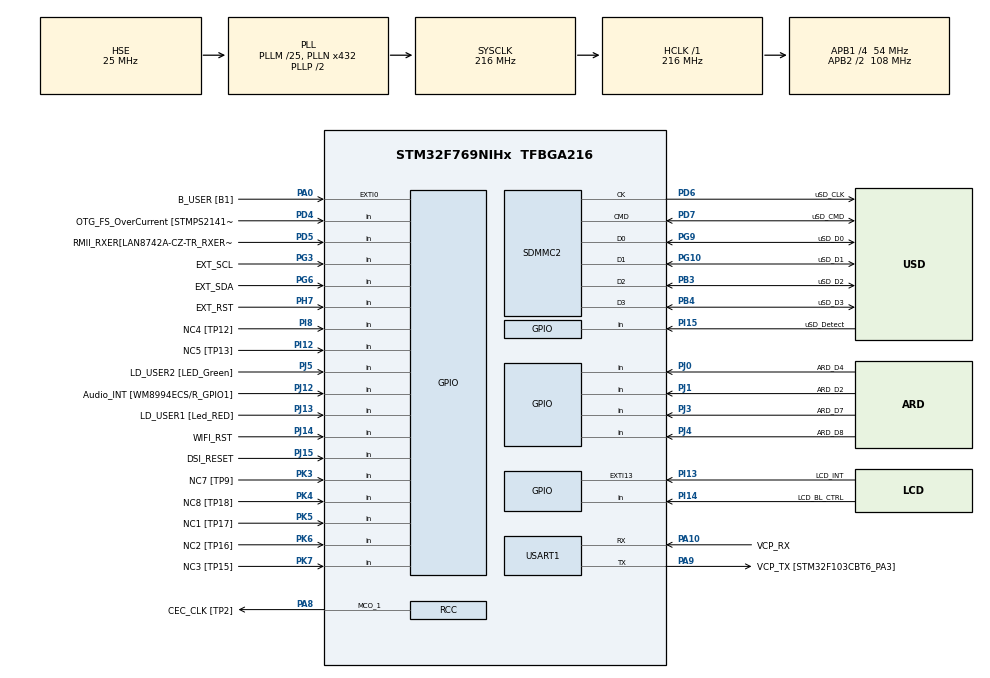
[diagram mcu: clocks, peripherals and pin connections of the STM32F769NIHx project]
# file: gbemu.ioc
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DSIHOST_CKN.GPIO_Label=DSI_CK_N
DSIHOST_CKN.Signal=DSIHOST_CKN
DSIHOST_CKP.GPIO_Label=DSI_CK_P
DSIHOST_CKP.Signal=DSIHOST_CKP
DSIHOST_D0N.GPIO_Label=DSI_D0_N
DSIHOST_D0N.Signal=DSIHOST_D0N
DSIHOST_D0P.GPIO_Label=DSI_D0_p
DSIHOST_D0P.Signal=DSIHOST_D0P
DSIHOST_D1N.GPIO_Label=DSI_D1_N
DSIHOST_D1N.Signal=DSIHOST_D1N
DSIHOST_D1P.GPIO_Label=DSI_D1_P
DSIHOST_D1P.Signal=DSIHOST_D1P
Dma.Request0=SDMMC2_RX
Dma.Request1=SDMMC2_TX
Dma.SDMMC2_RX.0.Direction=DMA_PERIPH_TO_MEMORY
Dma.SDMMC2_RX.0.FIFOMode=DMA_FIFOMODE_ENABLE
Dma.SDMMC2_RX.0.FIFOThreshold=DMA_FIFO_THRESHOLD_FULL
Dma.SDMMC2_RX.0.Instance=DMA2_Stream0
Dma.SDMMC2_RX.0.MemBurst=DMA_MBURST_INC4
Dma.SDMMC2_RX.0.MemDataAlignment=DMA_MDATAALIGN_WORD
Dma.SDMMC2_RX.0.MemInc=DMA_MINC_ENABLE
Dma.SDMMC2_RX.0.Mode=DMA_PFCTRL
Dma.SDMMC2_RX.0.PeriphBurst=DMA_PBURST_INC4
Dma.SDMMC2_RX.0.PeriphDataAlignment=DMA_PDATAALIGN_WORD
Dma.SDMMC2_RX.0.PeriphInc=DMA_PINC_DISABLE
Dma.SDMMC2_RX.0.Priority=DMA_PRIORITY_LOW
Dma.SDMMC2_TX.1.Direction=DMA_MEMORY_TO_PERIPH
Dma.SDMMC2_TX.1.FIFOMode=DMA_FIFOMODE_ENABLE
Dma.SDMMC2_TX.1.FIFOThreshold=DMA_FIFO_THRESHOLD_FULL
Dma.SDMMC2_TX.1.Instance=DMA2_Stream5
Dma.SDMMC2_TX.1.MemBurst=DMA_MBURST_INC4
Dma.SDMMC2_TX.1.MemDataAlignment=DMA_MDATAALIGN_WORD
Dma.SDMMC2_TX.1.MemInc=DMA_MINC_ENABLE
Dma.SDMMC2_TX.1.Mode=DMA_PFCTRL
Dma.SDMMC2_TX.1.PeriphBurst=DMA_PBURST_INC4
Dma.SDMMC2_TX.1.PeriphDataAlignment=DMA_PDATAALIGN_WORD
Dma.SDMMC2_TX.1.PeriphInc=DMA_PINC_DISABLE
Dma.SDMMC2_TX.1.Priority=DMA_PRIORITY_LOW
FATFS.BSP.number=1
FATFS.USE_DMA_CODE_SD=1
FATFS._MAX_SS=512
FATFS._MIN_SS=512
FATFS0.BSP.STBoard=false
FATFS0.BSP.api=Unknown
FATFS0.BSP.i2caddr=0
FATFS0.BSP.instance=PI15
FATFS0.BSP.ip=GPIO
FATFS0.BSP.mode=Input
FATFS0.BSP.name=Detect_SDIO
FATFS0.BSP.solution=PI15
FREERTOS.Tasks01=defaultTask,-3,128,StartDefaultTask,Default,NULL,Dynamic,NULL,NULL;cpu_task,-1,512,cpu_start,Default,NULL,Dynamic,NULL,NULL;ui_task,0,512,ui_start,Default,NULL,Dynamic,NULL,NULL
FREERTOS.configUSE_NEWLIB_REENTRANT=1
Mcu.Family=STM32F7
Mcu.Name=STM32F769NIHx
Mcu.Package=TFBGA216
NVIC.DMA2_Stream0_IRQn=true\:5\:0\:false\:false\:true\:true\:false\:true
NVIC.DMA2_Stream5_IRQn=true\:5\:0\:false\:false\:true\:true\:false\:true
NVIC.PriorityGroup=NVIC_PRIORITYGROUP_4
NVIC.SDMMC2_IRQn=true\:5\:0\:false\:false\:true\:true\:true\:true
NVIC.TIM1_UP_TIM10_IRQn=true\:15\:0\:false\:false\:true\:false\:false\:true
NVIC.TimeBase=TIM1_UP_TIM10_IRQn
NVIC.TimeBaseIP=TIM1
PA0/WKUP.GPIO_Label=B_USER [B1]
PA0/WKUP.Signal=GPXTI0
PA1.GPIO_Label=RMII_REF_CLK [LAN8742A-CZ-TR_REFCLK0]
PA1.Signal=ETH_REF_CLK
PA10.GPIO_Label=VCP_RX 
PA10.Mode=Asynchronous
PA10.Signal=USART1_RX
PA11.GPIO_Label=SPI2_NSS
PA11.Signal=SPI2_NSS
PA12.GPIO_Label=ARD_D13/SCK
PA12.GPIO_Mode=GPIO_MODE_AF_PP
PA12.GPIO_PuPd=GPIO_NOPULL
PA12.GPIO_Speed=GPIO_SPEED_FREQ_LOW
PA12.Signal=SPI2_SCK
PA13.GPIO_Label=SWDIO
PA13.Mode=Serial_Wire
PA13.Signal=SYS_JTMS-SWDIO
PA14.GPIO_Label=SWCLK
PA14.Mode=Serial_Wire
PA14.Signal=SYS_JTCK-SWCLK
PA15.GPIO_Label=CEC
PA15.Signal=CEC
PA2.GPIO_Label=RMII_MDIO [LAN8742A-CZ-TR_MDIO]
PA2.Signal=ETH_MDIO
PA3.GPIO_Label=ULPI_D0 [USB3320C-EZK_D0]
PA3.Signal=USB_OTG_HS_ULPI_D0
PA4.GPIO_Label=ARD_A1
PA4.Signal=ADCx_IN4
PA5.GPIO_Label=ULPI_CLK [USB3320C-EZK_CLKOUT]
PA5.Signal=USB_OTG_HS_ULPI_CK
PA6.GPIO_Label=ARD_A0
PA6.Signal=ADCx_IN6
PA7.GPIO_Label=RMII_CRS_DV [LAN8742A-CZ-TR_CRS_DV]
PA7.Signal=ETH_CRS_DV
PA8.GPIO_Label=CEC_CLK [TP2]
PA8.Mode=Clock-out-1
PA8.Signal=RCC_MCO_1
PA9.GPIO_Label=VCP_TX [STM32F103CBT6_PA3]
PA9.GPIO_Mode=GPIO_MODE_AF_PP
PA9.GPIO_PuPd=GPIO_NOPULL
PA9.GPIO_Speed=GPIO_SPEED_FREQ_LOW
PA9.Mode=Asynchronous
PA9.Signal=USART1_TX
PB0.GPIO_Label=ULPI_D1 [USB3320C-EZK_D1]
PB0.Signal=USB_OTG_HS_ULPI_D1
PB1.GPIO_Label=ULPI_D2 [USB3320C-EZK_D2]
PB1.Signal=USB_OTG_HS_ULPI_D2
PB10.GPIO_Label=ULPI_D3 [USB3320C-EZK_D3]
PB10.Signal=USB_OTG_HS_ULPI_D3
PB11.GPIO_Label=ULPI_D4 [USB3320C-EZK_D4]
PB11.Signal=USB_OTG_HS_ULPI_D4
PB12.GPIO_Label=ULPI_D5 [USB3320C-EZK_D5]
PB12.Signal=USB_OTG_HS_ULPI_D5
PB13.GPIO_Label=ULPI_D6 [USB3320C-EZK_D6]
PB13.Signal=USB_OTG_HS_ULPI_D6
PB14.GPIO_Label=ARDUINO MISO/D12
PB14.GPIO_Mode=GPIO_MODE_AF_PP
PB14.GPIO_PuPd=GPIO_NOPULL
PB14.GPIO_Speed=GPIO_SPEED_FREQ_LOW
PB14.Signal=SPI2_MISO
PB15.GPIO_Label=ARDUINO MOSI/PWM/D11
PB15.GPIO_Mode=GPIO_MODE_AF_PP
PB15.GPIO_PuPd=GPIO_NOPULL
PB15.GPIO_Speed=GPIO_SPEED_FREQ_LOW
PB15.Signal=SPI2_MOSI
PB2.Signal=QUADSPI_CLK
PB3.GPIO_Label=uSD_D2
PB3.Mode=SD_4_bits_Wide_bus
PB3.Signal=SDMMC2_D2
PB4.GPIO_Label=uSD_D3
PB4.Mode=SD_4_bits_Wide_bus
PB4.Signal=SDMMC2_D3
PB5.GPIO_Label=ULPI_D7 [USB3320C-EZK_D7]
PB5.Signal=USB_OTG_HS_ULPI_D7
PB6.GPIO_Label=QSPI_NCS [N25Q128A13EF840E_S]
PB6.Signal=QUADSPI_BK1_NCS
PB7.GPIO_Label=AUDIO_SDA [WM8994ECS/R_SDA]
PB7.Signal=I2C4_SDA
PB8.GPIO_Label=ARDUINO SCL/D15
PB8.GPIO_Mode=GPIO_MODE_AF_OD
PB8.GPIO_PuPd=GPIO_NOPULL
PB8.GPIO_Speed=GPIO_SPEED_FREQ_LOW
PB8.Signal=I2C1_SCL
PB9.GPIO_Label=ARDUINO SDA/D14
PB9.GPIO_Mode=GPIO_MODE_AF_OD
PB9.GPIO_PuPd=GPIO_NOPULL
PB9.GPIO_Speed=GPIO_SPEED_FREQ_LOW
PB9.Signal=I2C1_SDA
PC0.GPIO_Label=ULPI_STP [USB3320C-EZK_STP]
PC0.Signal=USB_OTG_HS_ULPI_STP
PC1.GPIO_Label=RMII_MDC [LAN8742A-CZ-TR_MDC]
PC1.Signal=ETH_MDC
PC10.GPIO_Label=QSPI_D1 [MT25QL512ABB1EW9_DQ1]
PC10.Signal=QUADSPI_BK1_IO1
PC11.GPIO_Label=DFSDM_DATIN5 [TP100]
PC11.Signal=S_DATAIN5DFSDM1
PC12.GPIO_Label=WIFI_RX
PC12.Signal=UART5_TX
PC14/OSC32_IN.GPIO_Label=RCC_OSC32_IN
PC14/OSC32_IN.Signal=RCC_OSC32_IN
PC15/OSC32_OUT.GPIO_Label=RCC_OSC32_OUT
PC15/OSC32_OUT.Signal=RCC_OSC32_OUT
PC2.GPIO_Label=ARD_A2
PC2.Signal=ADCx_IN12
PC3.GPIO_Label=DFSDM_DATIN1 [TP101]
PC3.Signal=S_DATAIN1DFSDM1
PC4.GPIO_Label=RMII_RXD0 [LAN8742A-CZ-TR_RXD0]
PC4.Signal=ETH_RXD0
PC5.GPIO_Label=RMII_RXD1 [LAN8742A-CZ-TR_RXD1]
PC5.Signal=ETH_RXD1
PC6.GPIO_Label=ARDUINO TX/D1
PC6.Signal=USART6_TX
PC7.GPIO_Label=ARD_D0/RX
PC7.Signal=USART6_RX
PC8.GPIO_Label=ARD_D5/PWM
PC8.Signal=S_TIM3_CH3
PC9.GPIO_Label=QSPI_D0 [N25Q128A13EF840E_DQ0]
PC9.Signal=QUADSPI_BK1_IO0
PD0.GPIO_Label=FMC_D2 [MT48LC4M32B2B5-6A_DQ2]
PD0.Signal=FMC_D2_DA2
PD1.GPIO_Label=FMC_D3 [MT48LC4M32B2B5-6A_DQ3]
PD1.Signal=FMC_D3_DA3
PD10.GPIO_Label=FMC_D15 [MT48LC4M32B2B5-6A_DQ15]
PD10.Signal=FMC_D15_DA15
PD11.GPIO_Label=SPDIF_TX [TP20]
PD11.Signal=SAI2_SD_A
PD12.GPIO_Label=AUDIO_SCL [WM8994ECS/R_SCLK]
PD12.Signal=I2C4_SCL
PD13.GPIO_Label=QSPI_D3 [N25Q128A13EF840E_DQ3]
PD13.Signal=QUADSPI_BK1_IO3
PD14.GPIO_Label=FMC_D0 [MT48LC4M32B2B5-6A_DQ0]
PD14.Signal=FMC_D0_DA0
PD15.GPIO_Label=FMC_D1 [MT48LC4M32B2B5-6A_DQ1]
PD15.Signal=FMC_D1_DA1
PD2.GPIO_Label=WIFI_TX
PD2.Signal=UART5_RX
PD3.GPIO_Label=DFSDM_CKOUT [TP102]
PD3.Signal=S_CKOUTDFSDM1
PD4.GPIO_Label=OTG_FS_OverCurrent [STMPS2141STR_Fault]
PD4.Signal=GPIO_Input
PD5.GPIO_Label=RMII_RXER[LAN8742A-CZ-TR_RXERR]
PD5.Signal=GPIO_Input
PD6.GPIO_Label=uSD_CLK
PD6.Mode=SD_4_bits_Wide_bus
PD6.Signal=SDMMC2_CK
PD7.GPIO_Label=uSD_CMD
PD7.Mode=SD_4_bits_Wide_bus
PD7.Signal=SDMMC2_CMD
PD8.GPIO_Label=FMC_D13 [MT48LC4M32B2B5-6A_DQ13]
PD8.Signal=FMC_D13_DA13
PD9.GPIO_Label=FMC_D14 [MT48LC4M32B2B5-6A_DQ14]
PD9.Signal=FMC_D14_DA14
PE0.GPIO_Label=FMC_NBL0 [MT48LC4M32B2B5-6A_DQM0]
PE0.Signal=FMC_NBL0
PE1.GPIO_Label=FMC_NBL1 [MT48LC4M32B2B5-6A_DQM1]
PE1.Signal=FMC_NBL1
PE10.GPIO_Label=FMC_D7 [MT48LC4M32B2B5-6A_DQ7]
PE10.Signal=FMC_D7_DA7
PE11.GPIO_Label=FMC_D8 [MT48LC4M32B2B5-6A_DQ8]
PE11.Signal=FMC_D8_DA8
PE12.GPIO_Label=FMC_D9 [MT48LC4M32B2B5-6A_DQ9]
PE12.Signal=FMC_D9_DA9
PE13.GPIO_Label=FMC_D10 [MT48LC4M32B2B5-6A_DQ10]
PE13.Signal=FMC_D10_DA10
PE14.GPIO_Label=FMC_D11 [MT48LC4M32B2B5-6A_DQ11]
PE14.Signal=FMC_D11_DA11
PE15.GPIO_Label=FMC_D12 [MT48LC4M32B2B5-6A_DQ12]
PE15.Signal=FMC_D12_DA12
PE2.GPIO_Label=QSPI_D2 [N25Q128A13EF840E_DQ2]
PE2.Signal=QUADSPI_BK1_IO2
PE3.GPIO_Label=SAI1_SDB [WM8994ECS/R_ADCDAT1]
PE3.Signal=SAI1_SD_B
PE4.GPIO_Label=SAI1_FSA [WM8994ECS/R_LRCLK1]
PE4.Signal=SAI1_FS_A
PE5.GPIO_Label=SAI1_SCKA [WM8994ECS/R_BCLK1]
PE5.Signal=SAI1_SCK_A
PE6.GPIO_Label=SAI1_SDA [WM8994ECS/R_DACDAT1]
PE6.Signal=SAI1_SD_A
PE7.GPIO_Label=FMC_D4 [MT48LC4M32B2B5-6A_DQ4]
PE7.Signal=FMC_D4_DA4
PE8.GPIO_Label=FMC_D5 [MT48LC4M32B2B5-6A_DQ5]
PE8.Signal=FMC_D5_DA5
PE9.GPIO_Label=FMC_D6 [MT48LC4M32B2B5-6A_DQ6]
PE9.Signal=FMC_D6_DA6
PF0.GPIO_Label=FMC_A0 [MT48LC4M32B2B5-6A_A0]
PF0.Signal=FMC_A0
PF1.GPIO_Label=FMC_A1 [MT48LC4M32B2B5-6A_A1]
PF1.Signal=FMC_A1
PF10.GPIO_Label=ARDUINO A1
PF10.GPIO_Mode=GPIO_MODE_ANALOG
PF10.GPIO_PuPd=GPIO_NOPULL
PF10.Signal=ADC3_IN8
PF11.GPIO_Label=FMC_SDNRAS [MT48LC4M32B2B5-6A_RAS]
PF11.Signal=FMC_SDNRAS
PF12.GPIO_Label=FMC_A6 [MT48LC4M32B2B5-6A_A6]
PF12.Signal=FMC_A6
PF13.GPIO_Label=FMC_A7 [MT48LC4M32B2B5-6A_A7]
PF13.Signal=FMC_A7
PF14.GPIO_Label=FMC_A8 [MT48LC4M32B2B5-6A_A8]
PF14.Signal=FMC_A8
PF15.GPIO_Label=FMC_A9 [MT48LC4M32B2B5-6A_A9]
PF15.Signal=FMC_A9
PF2.GPIO_Label=FMC_A2 [MT48LC4M32B2B5-6A_A2]
PF2.Signal=FMC_A2
PF3.GPIO_Label=FMC_A3 [MT48LC4M32B2B5-6A_A3]
PF3.Signal=FMC_A3
PF4.GPIO_Label=FMC_A4 [MT48LC4M32B2B5-6A_A4]
PF4.Signal=FMC_A4
PF5.GPIO_Label=FMC_A5 [MT48LC4M32B2B5-6A_A5]
PF5.Signal=FMC_A5
PF6.GPIO_Label=ARD_D3/PWM
PF6.Signal=S_TIM10_CH1
PF7.GPIO_Label=ARD_D6/PWM
PF7.Signal=S_TIM11_CH1
PF8.GPIO_Label=ARDUINO A3
PF8.GPIO_Mode=GPIO_MODE_ANALOG
PF8.GPIO_PuPd=GPIO_NOPULL
PF8.Signal=ADC3_IN6
PF9.GPIO_Label=ARDUINO A2
PF9.GPIO_Mode=GPIO_MODE_ANALOG
PF9.GPIO_PuPd=GPIO_NOPULL
PF9.Signal=ADC3_IN7
PG0.GPIO_Label=FMC_A10 [MT48LC4M32B2B5-6A_A10]
PG0.Signal=FMC_A10
PG1.GPIO_Label=FMC_A11 [MT48LC4M32B2B5-6A_A11]
PG1.Signal=FMC_A11
PG10.GPIO_Label=uSD_D1
PG10.Mode=SD_4_bits_Wide_bus
PG10.Signal=SDMMC2_D1
PG11.GPIO_Label=RMII_TX_EN [LAN8742A-CZ-TR_TXEN]
PG11.Signal=ETH_TX_EN
PG12.GPIO_Label=SPDIF_RX [74LVC1G04SE_4]
PG12.Signal=SPDIFRX_IN1
PG13.GPIO_Label=RMII_TXD0 [LAN8742A-CZ-TR_TXD0]
PG13.Signal=ETH_TXD0
PG14.GPIO_Label=RMII_TXD1 [LAN8742A-CZ-TR_TXD1]
PG14.Signal=ETH_TXD1
PG15.GPIO_Label=FMC_SDNCAS [MT48LC4M32B2B5-6A_CAS]
PG15.Signal=FMC_SDNCAS
PG2.GPIO_Label=FMC_A12
PG2.Signal=FMC_A12
PG3.GPIO_Label=EXT_SCL
PG3.Signal=GPIO_Input
PG4.GPIO_Label=FMC_BA0 [MT48LC4M32B2B5-6A_BA0]
PG4.Signal=FMC_A14_BA0
PG5.GPIO_Label=FMC_BA1 [MT48LC4M32B2B5-6A_BA1]
PG5.Signal=FMC_A15_BA1
PG6.GPIO_Label=EXT_SDA
PG6.Signal=GPIO_Input
PG7.GPIO_Label=SAI1_MCLKA [WM8994ECS/R_MCLK1]
PG7.Signal=SAI1_MCLK_A
PG8.GPIO_Label=FMC_SDCLK [MT48LC4M32B2B5-6A_CLK]
PG8.Signal=FMC_SDCLK
PG9.GPIO_Label=uSD_D0
PG9.Mode=SD_4_bits_Wide_bus
PG9.Signal=SDMMC2_D0
PH0/OSC_IN.GPIO_Label=OSC_25M [NZ2520SB-25.00M_OUT]
PH0/OSC_IN.Mode=HSE-External-Oscillator
PH0/OSC_IN.Signal=RCC_OSC_IN
PH1/OSC_OUT.Mode=HSE-External-Oscillator
PH1/OSC_OUT.Signal=RCC_OSC_OUT
PH10.GPIO_Label=FMC_D18 [MT48LC4M32B2B5-6A_DQ18]
PH10.Signal=FMC_D18
PH11.GPIO_Label=FMC_D19 [MT48LC4M32B2B5-6A_DQ19]
PH11.Signal=FMC_D19
PH12.GPIO_Label=D20
PH12.Signal=FMC_D20
PH13.GPIO_Label=D21
PH13.Signal=FMC_D21
PH14.GPIO_Label=D22
PH14.Signal=FMC_D22
PH15.GPIO_Label=D23
PH15.Signal=FMC_D23
PH2.GPIO_Label=FMC_SDCKE0 [MT48LC4M32B2B5-6A_CKE]
PH2.Signal=FMC_SDCKE0
PH3.GPIO_Label=FMC_SDNE0 [MT48LC4M32B2B5-6A_CS]
PH3.Signal=FMC_SDNE0
PH4.GPIO_Label=ULPI_NXT [USB3320C-EZK_NXT]
PH4.Signal=USB_OTG_HS_ULPI_NXT
PH5.GPIO_Label=FMC_SDNME [MT48LC4M32B2B5-6A_WE]
PH5.Signal=FMC_SDNWE
PH6.GPIO_Label=ARDUINO PWM/D6
PH6.Signal=S_TIM12_CH1
PH7.GPIO_Label=EXT_RST
PH7.Signal=GPIO_Input
PH8.GPIO_Label=FMC_D16 [MT48LC4M32B2B5-6A_DQ16]
PH8.Signal=FMC_D16
PH9.GPIO_Label=FMC_D\!7 [MT48LC4M32B2B5-6A_DQ17]
PH9.Signal=FMC_D17
PI0.GPIO_Label=D24
PI0.Signal=FMC_D24
PI1.GPIO_Label=D25
PI1.Signal=FMC_D25
PI10.GPIO_Label=D31
PI10.Signal=FMC_D31
PI11.GPIO_Label=ULPI_DIR [USB3320C-EZK_DIR]
PI11.Signal=USB_OTG_HS_ULPI_DIR
PI12.GPIO_Label=NC5 [TP13]
PI12.Signal=GPIO_Input
PI13.GPIO_Label=LCD_INT
PI13.GPIO_ModeDefaultEXTI=GPIO_MODE_EVT_RISING
PI13.Signal=GPXTI13
PI14.GPIO_Label=LCD_BL_CTRL
PI14.Signal=GPIO_Input
PI15.GPIO_Label=uSD_Detect
PI15.Signal=GPIO_Input
PI2.GPIO_Label=D26
PI2.Signal=FMC_D26
PI3.GPIO_Label=D27
PI3.Signal=FMC_D27
PI4.GPIO_Label=FMC_NBL2 [MT48LC4M32B2B5-6A_DQM2]
PI4.Signal=FMC_NBL2
PI5.GPIO_Label=FMC_NBL3 [MT48LC4M32B2B5-6A_DQM3]
PI5.Signal=FMC_NBL3
PI6.GPIO_Label=D28
PI6.Signal=FMC_D28
PI7.GPIO_Label=D29
PI7.Signal=FMC_D29
PI8.GPIO_Label=NC4 [TP12]
PI8.Signal=GPIO_Input
PI9.GPIO_Label=D30
PI9.Signal=FMC_D30
PJ0.GPIO_Label=ARD_D4
PJ0.Signal=GPIO_Input
PJ1.GPIO_Label=ARD_D2
PJ1.Signal=GPIO_Input
PJ12.GPIO_Label=Audio_INT [WM8994ECS/R_GPIO1]
PJ12.Signal=GPIO_Input
PJ13.GPIO_Label=LD_USER1 [Led_RED]
PJ13.Signal=GPIO_Input
PJ14.GPIO_Label=WIFI_RST
PJ14.Signal=GPIO_Input
PJ15.GPIO_Label=DSI_RESET
PJ15.Signal=GPIO_Input
PJ2.GPIO_Label=DSIHOST_TE
PJ2.Signal=DSIHOST_TE
PJ3.GPIO_Label=ARD_D7
PJ3.Signal=GPIO_Input
PJ4.GPIO_Label=ARD_D8
PJ4.Signal=GPIO_Input
PJ5.GPIO_Label=LD_USER2 [LED_Green]
PJ5.Signal=GPIO_Input
PK3.GPIO_Label=NC7 [TP9]
PK3.Signal=GPIO_Input
PK4.GPIO_Label=NC8 [TP18]
PK4.Signal=GPIO_Input
PK5.GPIO_Label=NC1 [TP17]
PK5.Signal=GPIO_Input
PK6.GPIO_Label=NC2 [TP16]
PK6.Signal=GPIO_Input
PK7.GPIO_Label=NC3 [TP15]
PK7.Signal=GPIO_Input
ProjectManager.HeapSize=0x400
ProjectManager.StackSize=0x800
ProjectManager.TargetToolchain=STM32CubeIDE
RCC.AHBFreq_Value=216000000
RCC.APB1CLKDivider=RCC_HCLK_DIV4
RCC.APB1Freq_Value=54000000
RCC.APB1TimFreq_Value=108000000
RCC.APB2CLKDivider=RCC_HCLK_DIV2
RCC.APB2Freq_Value=108000000
RCC.APB2TimFreq_Value=216000000
RCC.CortexFreq_Value=216000000
RCC.HCLKFreq_Value=216000000
RCC.HSE_VALUE=25000000
RCC.HSI_VALUE=16000000
RCC.LSE_VALUE=32768
RCC.PLLM=25
RCC.PLLN=432
RCC.PLLQ=9
RCC.PLLSAIQ=3
RCC.PLLSourceVirtual=RCC_PLLSOURCE_HSE
RCC.SDMMC2ClockSelection=RCC_SDMMC2CLKSOURCE_CLK48
RCC.SYSCLKFreq_VALUE=216000000
RCC.SYSCLKSource=RCC_SYSCLKSOURCE_PLLCLK
RCC.USBFreq_Value=48000000
RCC.VCOOutputFreq_Value=432000000
SH.ADCx_IN12.0=ADC1_IN12
SH.ADCx_IN4.0=ADC1_IN4
SH.ADCx_IN6.0=ADC1_IN6
SH.FMC_A0.0=FMC_A0
SH.FMC_A1.0=FMC_A1
SH.FMC_A10.0=FMC_A10
SH.FMC_A11.0=FMC_A11
SH.FMC_A12.0=FMC_A12
SH.FMC_A14_BA0.0=FMC_BA0
SH.FMC_A15_BA1.0=FMC_BA1
SH.FMC_A2.0=FMC_A2
SH.FMC_A3.0=FMC_A3
SH.FMC_A4.0=FMC_A4
SH.FMC_A5.0=FMC_A5
SH.FMC_A6.0=FMC_A6
SH.FMC_A7.0=FMC_A7
SH.FMC_A8.0=FMC_A8
SH.FMC_A9.0=FMC_A9
SH.FMC_D0_DA0.0=FMC_D0
SH.FMC_D10_DA10.0=FMC_D10
SH.FMC_D11_DA11.0=FMC_D11
SH.FMC_D12_DA12.0=FMC_D12
SH.FMC_D13_DA13.0=FMC_D13
SH.FMC_D14_DA14.0=FMC_D14
SH.FMC_D15_DA15.0=FMC_D15
SH.FMC_D16.0=FMC_D16
SH.FMC_D17.0=FMC_D17
SH.FMC_D18.0=FMC_D18
SH.FMC_D19.0=FMC_D19
SH.FMC_D1_DA1.0=FMC_D1
SH.FMC_D20.0=FMC_D20
SH.FMC_D21.0=FMC_D21
SH.FMC_D22.0=FMC_D22
SH.FMC_D23.0=FMC_D23
SH.FMC_D24.0=FMC_D24
SH.FMC_D25.0=FMC_D25
SH.FMC_D26.0=FMC_D26
SH.FMC_D27.0=FMC_D27
SH.FMC_D28.0=FMC_D28
SH.FMC_D29.0=FMC_D29
SH.FMC_D2_DA2.0=FMC_D2
SH.FMC_D30.0=FMC_D30
SH.FMC_D31.0=FMC_D31
SH.FMC_D3_DA3.0=FMC_D3
SH.FMC_D4_DA4.0=FMC_D4
SH.FMC_D5_DA5.0=FMC_D5
SH.FMC_D6_DA6.0=FMC_D6
SH.FMC_D7_DA7.0=FMC_D7
SH.FMC_D8_DA8.0=FMC_D8
SH.FMC_D9_DA9.0=FMC_D9
SH.FMC_NBL0.0=FMC_NBL0
SH.FMC_NBL1.0=FMC_NBL1
SH.FMC_NBL2.0=FMC_NBL2
SH.FMC_NBL3.0=FMC_NBL3
SH.FMC_SDCLK.0=FMC_SDCLK
SH.FMC_SDNCAS.0=FMC_SDNCAS
SH.FMC_SDNRAS.0=FMC_SDNRAS
SH.FMC_SDNWE.0=FMC_SDNWE
SH.S_CKOUTDFSDM1.0=DFSDM1_CKOUT
SH.S_DATAIN1DFSDM1.0=DFSDM1_DATIN1
SH.S_DATAIN5DFSDM1.0=DFSDM1_DATIN5
SH.S_TIM10_CH1.0=TIM10_CH1
SH.S_TIM11_CH1.0=TIM11_CH1
SH.S_TIM12_CH1.0=TIM12_CH1
SH.S_TIM3_CH3.0=TIM3_CH3
USART1.VirtualMode-Asynchronous=VM_ASYNC
VP_CRC_VS_CRC.Mode=CRC_Activate
VP_FATFS_VS_SDIO.Mode=SDIO
VP_FREERTOS_VS_CMSIS_V1.Mode=CMSIS_V1
VP_SYS_VS_tim1.Mode=TIM1
board=STM32F769I-DISCO

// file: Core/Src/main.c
/* USER CODE BEGIN Header */
/**
  ******************************************************************************
  * @file           : main.c
  * @brief          : Main program body
  ******************************************************************************
  * @attention
  *
  * Copyright (c) 2021 STMicroelectronics.
  * All rights reserved.
  *
  * This software is licensed under terms that can be found in the LICENSE file
  * in the root directory of this software component.
  * If no LICENSE file comes with this software, it is provided AS-IS.
  *
  ******************************************************************************
  */
/* USER CODE END Header */
#include "main.h"
#include "cmsis_os.h"
#include "fatfs.h"

/* USER CODE BEGIN Includes */
#include "string.h"
#include "emu.h"
/* USER CODE END Includes */

CRC_HandleTypeDef hcrc;

SD_HandleTypeDef hsd2;
DMA_HandleTypeDef hdma_sdmmc2_rx;
DMA_HandleTypeDef hdma_sdmmc2_tx;

UART_HandleTypeDef huart1;

osThreadId defaultTaskHandle;
osThreadId cpu_taskHandle;
osThreadId ui_taskHandle;

void SystemClock_Config(void);
static void MX_GPIO_Init(void);
static void MX_SDMMC2_SD_Init(void);
static void MX_DMA_Init(void);
static void MX_CRC_Init(void);
static void MX_USART1_UART_Init(void);
void StartDefaultTask(void const * argument);
void cpu_start(void const * argument);
void ui_start(void const * argument);

/* USER CODE BEGIN 0 */
int _write(int file, char *ptr, int len)
{
  HAL_UART_Transmit(&huart1, (uint8_t*)ptr, len, HAL_MAX_DELAY);
  return len;
}
/* USER CODE END 0 */

int main(void)
{

  /* MCU Configuration--------------------------------------------------------*/

  /* Reset of all peripherals, Initializes the Flash interface and the Systick. */
  HAL_Init();

  /* Configure the system clock */
  SystemClock_Config();

  /* Initialize all configured peripherals */
  MX_GPIO_Init();
  MX_SDMMC2_SD_Init();
  MX_DMA_Init();
  MX_FATFS_Init();
  MX_CRC_Init();
  MX_USART1_UART_Init();

  /* Create the thread(s) */
  /* definition and creation of defaultTask */
  osThreadDef(defaultTask, StartDefaultTask, osPriorityIdle, 0, 128);
  defaultTaskHandle = osThreadCreate(osThread(defaultTask), NULL);

  /* definition and creation of cpu_task */
  osThreadDef(cpu_task, cpu_start, osPriorityBelowNormal, 0, 512);
  cpu_taskHandle = osThreadCreate(osThread(cpu_task), NULL);

  /* definition and creation of ui_task */
  osThreadDef(ui_task, ui_start, osPriorityNormal, 0, 512);
  ui_taskHandle = osThreadCreate(osThread(ui_task), NULL);

  /* Start scheduler */
  osKernelStart();

  /* We should never get here as control is now taken by the scheduler */
  /* Infinite loop */
  while (1)
  {

  }
}

void SystemClock_Config(void)
{
  RCC_OscInitTypeDef RCC_OscInitStruct = {0};
  RCC_ClkInitTypeDef RCC_ClkInitStruct = {0};

  /** Configure the main internal regulator output voltage
  */
  __HAL_RCC_PWR_CLK_ENABLE();
  __HAL_PWR_VOLTAGESCALING_CONFIG(PWR_REGULATOR_VOLTAGE_SCALE1);
  /** Initializes the RCC Oscillators according to the specified parameters
  * in the RCC_OscInitTypeDef structure.
  */
  RCC_OscInitStruct.OscillatorType = RCC_OSCILLATORTYPE_HSI|RCC_OSCILLATORTYPE_HSE;
  RCC_OscInitStruct.HSEState = RCC_HSE_ON;
  RCC_OscInitStruct.HSIState = RCC_HSI_ON;
  RCC_OscInitStruct.HSICalibrationValue = RCC_HSICALIBRATION_DEFAULT;
  RCC_OscInitStruct.PLL.PLLState = RCC_PLL_ON;
  RCC_OscInitStruct.PLL.PLLSource = RCC_PLLSOURCE_HSE;
  RCC_OscInitStruct.PLL.PLLM = 25;
  RCC_OscInitStruct.PLL.PLLN = 432;
  RCC_OscInitStruct.PLL.PLLP = RCC_PLLP_DIV2;
  RCC_OscInitStruct.PLL.PLLQ = 9;
  RCC_OscInitStruct.PLL.PLLR = 2;
  if (HAL_RCC_OscConfig(&RCC_OscInitStruct) != HAL_OK)
  {
    Error_Handler();
  }
  /** Activate the Over-Drive mode
  */
  if (HAL_PWREx_EnableOverDrive() != HAL_OK)
  {
    Error_Handler();
  }
  /** Initializes the CPU, AHB and APB buses clocks
  */
  RCC_ClkInitStruct.ClockType = RCC_CLOCKTYPE_HCLK|RCC_CLOCKTYPE_SYSCLK
                              |RCC_CLOCKTYPE_PCLK1|RCC_CLOCKTYPE_PCLK2;
  RCC_ClkInitStruct.SYSCLKSource = RCC_SYSCLKSOURCE_PLLCLK;
  RCC_ClkInitStruct.AHBCLKDivider = RCC_SYSCLK_DIV1;
  RCC_ClkInitStruct.APB1CLKDivider = RCC_HCLK_DIV4;
  RCC_ClkInitStruct.APB2CLKDivider = RCC_HCLK_DIV2;

  if (HAL_RCC_ClockConfig(&RCC_ClkInitStruct, FLASH_LATENCY_7) != HAL_OK)
  {
    Error_Handler();
  }
  HAL_RCC_MCOConfig(RCC_MCO1, RCC_MCO1SOURCE_HSI, RCC_MCODIV_1);
}

static void MX_CRC_Init(void)
{

  hcrc.Instance = CRC;
  hcrc.Init.DefaultPolynomialUse = DEFAULT_POLYNOMIAL_ENABLE;
  hcrc.Init.DefaultInitValueUse = DEFAULT_INIT_VALUE_ENABLE;
  hcrc.Init.InputDataInversionMode = CRC_INPUTDATA_INVERSION_NONE;
  hcrc.Init.OutputDataInversionMode = CRC_OUTPUTDATA_INVERSION_DISABLE;
  hcrc.InputDataFormat = CRC_INPUTDATA_FORMAT_BYTES;
  if (HAL_CRC_Init(&hcrc) != HAL_OK)
  {
    Error_Handler();
  }

}

static void MX_SDMMC2_SD_Init(void)
{

  hsd2.Instance = SDMMC2;
  hsd2.Init.ClockEdge = SDMMC_CLOCK_EDGE_RISING;
  hsd2.Init.ClockBypass = SDMMC_CLOCK_BYPASS_DISABLE;
  hsd2.Init.ClockPowerSave = SDMMC_CLOCK_POWER_SAVE_DISABLE;
  hsd2.Init.BusWide = SDMMC_BUS_WIDE_1B;
  hsd2.Init.HardwareFlowControl = SDMMC_HARDWARE_FLOW_CONTROL_DISABLE;
  hsd2.Init.ClockDiv = 0;

}

static void MX_USART1_UART_Init(void)
{

  huart1.Instance = USART1;
  huart1.Init.BaudRate = 115200;
  huart1.Init.WordLength = UART_WORDLENGTH_8B;
  huart1.Init.StopBits = UART_STOPBITS_1;
  huart1.Init.Parity = UART_PARITY_NONE;
  huart1.Init.Mode = UART_MODE_TX_RX;
  huart1.Init.HwFlowCtl = UART_HWCONTROL_NONE;
  huart1.Init.OverSampling = UART_OVERSAMPLING_16;
  huart1.Init.OneBitSampling = UART_ONE_BIT_SAMPLE_DISABLE;
  huart1.AdvancedInit.AdvFeatureInit = UART_ADVFEATURE_NO_INIT;
  if (HAL_UART_Init(&huart1) != HAL_OK)
  {
    Error_Handler();
  }

}

static void MX_DMA_Init(void)
{

  /* DMA controller clock enable */
  __HAL_RCC_DMA2_CLK_ENABLE();

  /* DMA interrupt init */
  /* DMA2_Stream0_IRQn interrupt configuration */
  HAL_NVIC_SetPriority(DMA2_Stream0_IRQn, 5, 0);
  HAL_NVIC_EnableIRQ(DMA2_Stream0_IRQn);
  /* DMA2_Stream5_IRQn interrupt configuration */
  HAL_NVIC_SetPriority(DMA2_Stream5_IRQn, 5, 0);
  HAL_NVIC_EnableIRQ(DMA2_Stream5_IRQn);

}

static void MX_GPIO_Init(void)
{
  GPIO_InitTypeDef GPIO_InitStruct = {0};

  /* GPIO Ports Clock Enable */
  __HAL_RCC_GPIOE_CLK_ENABLE();
  __HAL_RCC_GPIOG_CLK_ENABLE();
  __HAL_RCC_GPIOB_CLK_ENABLE();
  __HAL_RCC_GPIOD_CLK_ENABLE();
  __HAL_RCC_GPIOC_CLK_ENABLE();
  __HAL_RCC_GPIOA_CLK_ENABLE();
  __HAL_RCC_GPIOJ_CLK_ENABLE();
  __HAL_RCC_GPIOI_CLK_ENABLE();
  __HAL_RCC_GPIOK_CLK_ENABLE();
  __HAL_RCC_GPIOF_CLK_ENABLE();
  __HAL_RCC_GPIOH_CLK_ENABLE();

  /*Configure GPIO pins : SAI1_FSA_Pin SAI1_SDB_Pin SAI1_SCKA_Pin SAI1_SDA_Pin */
  GPIO_InitStruct.Pin = SAI1_FSA_Pin|SAI1_SDB_Pin|SAI1_SCKA_Pin|SAI1_SDA_Pin;
  GPIO_InitStruct.Mode = GPIO_MODE_AF_PP;
  GPIO_InitStruct.Pull = GPIO_NOPULL;
  GPIO_InitStruct.Speed = GPIO_SPEED_FREQ_LOW;
  GPIO_InitStruct.Alternate = GPIO_AF6_SAI1;
  HAL_GPIO_Init(GPIOE, &GPIO_InitStruct);

  /*Configure GPIO pin : QSPI_D2_Pin */
  GPIO_InitStruct.Pin = QSPI_D2_Pin;
  GPIO_InitStruct.Mode = GPIO_MODE_AF_PP;
  GPIO_InitStruct.Pull = GPIO_NOPULL;
  GPIO_InitStruct.Speed = GPIO_SPEED_FREQ_VERY_HIGH;
  GPIO_InitStruct.Alternate = GPIO_AF9_QUADSPI;
  HAL_GPIO_Init(QSPI_D2_GPIO_Port, &GPIO_InitStruct);

  /*Configure GPIO pins : RMII_TXD1_Pin RMII_TXD0_Pin RMII_TX_EN_Pin */
  GPIO_InitStruct.Pin = RMII_TXD1_Pin|RMII_TXD0_Pin|RMII_TX_EN_Pin;
  GPIO_InitStruct.Mode = GPIO_MODE_AF_PP;
  GPIO_InitStruct.Pull = GPIO_NOPULL;
  GPIO_InitStruct.Speed = GPIO_SPEED_FREQ_VERY_HIGH;
  GPIO_InitStruct.Alternate = GPIO_AF11_ETH;
  HAL_GPIO_Init(GPIOG, &GPIO_InitStruct);

  /*Configure GPIO pins : FMC_NBL1_Pin FMC_NBL0_Pin FMC_D5_Pin FMC_D6_Pin
                           FMC_D8_Pin FMC_D11_Pin FMC_D4_Pin FMC_D7_Pin
                           FMC_D9_Pin FMC_D12_Pin FMC_D10_Pin */
  GPIO_InitStruct.Pin = FMC_NBL1_Pin|FMC_NBL0_Pin|FMC_D5_Pin|FMC_D6_Pin
                          |FMC_D8_Pin|FMC_D11_Pin|FMC_D4_Pin|FMC_D7_Pin
                          |FMC_D9_Pin|FMC_D12_Pin|FMC_D10_Pin;
  GPIO_InitStruct.Mode = GPIO_MODE_AF_PP;
  GPIO_InitStruct.Pull = GPIO_NOPULL;
  GPIO_InitStruct.Speed = GPIO_SPEED_FREQ_VERY_HIGH;
  GPIO_InitStruct.Alternate = GPIO_AF12_FMC;
  HAL_GPIO_Init(GPIOE, &GPIO_InitStruct);

  /*Configure GPIO pins : ARDUINO_SCL_D15_Pin ARDUINO_SDA_D14_Pin */
  GPIO_InitStruct.Pin = ARDUINO_SCL_D15_Pin|ARDUINO_SDA_D14_Pin;
  GPIO_InitStruct.Mode = GPIO_MODE_AF_OD;
  GPIO_InitStruct.Pull = GPIO_NOPULL;
  GPIO_InitStruct.Speed = GPIO_SPEED_FREQ_LOW;
  GPIO_InitStruct.Alternate = GPIO_AF4_I2C1;
  HAL_GPIO_Init(GPIOB, &GPIO_InitStruct);

  /*Configure GPIO pins : ULPI_D7_Pin ULPI_D6_Pin ULPI_D5_Pin ULPI_D3_Pin
                           ULPI_D2_Pin ULPI_D1_Pin ULPI_D4_Pin */
  GPIO_InitStruct.Pin = ULPI_D7_Pin|ULPI_D6_Pin|ULPI_D5_Pin|ULPI_D3_Pin
                          |ULPI_D2_Pin|ULPI_D1_Pin|ULPI_D4_Pin;
  GPIO_InitStruct.Mode = GPIO_MODE_AF_PP;
  GPIO_InitStruct.Pull = GPIO_NOPULL;
  GPIO_InitStruct.Speed = GPIO_SPEED_FREQ_VERY_HIGH;
  GPIO_InitStruct.Alternate = GPIO_AF10_OTG_HS;
  HAL_GPIO_Init(GPIOB, &GPIO_InitStruct);

  /*Configure GPIO pin : WIFI_RX_Pin */
  GPIO_InitStruct.Pin = WIFI_RX_Pin;
  GPIO_InitStruct.Mode = GPIO_MODE_AF_PP;
  GPIO_InitStruct.Pull = GPIO_NOPULL;
  GPIO_InitStruct.Speed = GPIO_SPEED_FREQ_VERY_HIGH;
  GPIO_InitStruct.Alternate = GPIO_AF8_UART5;
  HAL_GPIO_Init(WIFI_RX_GPIO_Port, &GPIO_InitStruct);

  /*Configure GPIO pin : CEC_Pin */
  GPIO_InitStruct.Pin = CEC_Pin;
  GPIO_InitStruct.Mode = GPIO_MODE_AF_OD;
  GPIO_InitStruct.Pull = GPIO_NOPULL;
  GPIO_InitStruct.Speed = GPIO_SPEED_FREQ_LOW;
  GPIO_InitStruct.Alternate = GPIO_AF4_CEC;
  HAL_GPIO_Init(CEC_GPIO_Port, &GPIO_InitStruct);

  /*Configure GPIO pin : AUDIO_SDA_Pin */
  GPIO_InitStruct.Pin = AUDIO_SDA_Pin;
  GPIO_InitStruct.Mode = GPIO_MODE_AF_OD;
  GPIO_InitStruct.Pull = GPIO_NOPULL;
  GPIO_InitStruct.Speed = GPIO_SPEED_FREQ_VERY_HIGH;
  GPIO_InitStruct.Alternate = GPIO_AF11_I2C4;
  HAL_GPIO_Init(AUDIO_SDA_GPIO_Port, &GPIO_InitStruct);

  /*Configure GPIO pin : QSPI_NCS_Pin */
  GPIO_InitStruct.Pin = QSPI_NCS_Pin;
  GPIO_InitStruct.Mode = GPIO_MODE_AF_PP;
  GPIO_InitStruct.Pull = GPIO_NOPULL;
  GPIO_InitStruct.Speed = GPIO_SPEED_FREQ_VERY_HIGH;
  GPIO_InitStruct.Alternate = GPIO_AF10_QUADSPI;
  HAL_GPIO_Init(QSPI_NCS_GPIO_Port, &GPIO_InitStruct);

  /*Configure GPIO pins : FMC_SDNCAS_Pin FMC_SDCLK_Pin FMC_A11_Pin FMC_A12_Pin
                           FMC_A10_Pin FMC_BA1_Pin FMC_BA0_Pin */
  GPIO_InitStruct.Pin = FMC_SDNCAS_Pin|FMC_SDCLK_Pin|FMC_A11_Pin|FMC_A12_Pin
                          |FMC_A10_Pin|FMC_BA1_Pin|FMC_BA0_Pin;
  GPIO_InitStruct.Mode = GPIO_MODE_AF_PP;
  GPIO_InitStruct.Pull = GPIO_NOPULL;
  GPIO_InitStruct.Speed = GPIO_SPEED_FREQ_VERY_HIGH;
  GPIO_InitStruct.Alternate = GPIO_AF12_FMC;
  HAL_GPIO_Init(GPIOG, &GPIO_InitStruct);

  /*Configure GPIO pins : LD_USER1_Pin Audio_INT_Pin WIFI_RST_Pin DSI_RESET_Pin
                           ARD_D8_Pin LD_USER2_Pin ARD_D7_Pin ARD_D4_Pin
                           ARD_D2_Pin */
  GPIO_InitStruct.Pin = LD_USER1_Pin|Audio_INT_Pin|WIFI_RST_Pin|DSI_RESET_Pin
                          |ARD_D8_Pin|LD_USER2_Pin|ARD_D7_Pin|ARD_D4_Pin
                          |ARD_D2_Pin;
  GPIO_InitStruct.Mode = GPIO_MODE_INPUT;
  GPIO_InitStruct.Pull = GPIO_NOPULL;
  HAL_GPIO_Init(GPIOJ, &GPIO_InitStruct);

  /*Configure GPIO pins : FMC_D2_Pin FMC_D3_Pin FMC_D1_Pin FMC_D15_Pin
                           FMC_D0_Pin FMC_D14_Pin FMC_D13_Pin */
  GPIO_InitStruct.Pin = FMC_D2_Pin|FMC_D3_Pin|FMC_D1_Pin|FMC_D15_Pin
                          |FMC_D0_Pin|FMC_D14_Pin|FMC_D13_Pin;
  GPIO_InitStruct.Mode = GPIO_MODE_AF_PP;
  GPIO_InitStruct.Pull = GPIO_NOPULL;
  GPIO_InitStruct.Speed = GPIO_SPEED_FREQ_VERY_HIGH;
  GPIO_InitStruct.Alternate = GPIO_AF12_FMC;
  HAL_GPIO_Init(GPIOD, &GPIO_InitStruct);

  /*Configure GPIO pins : DFSDM_DATIN5_Pin DFSDM_DATIN1_Pin */
  GPIO_InitStruct.Pin = DFSDM_DATIN5_Pin|DFSDM_DATIN1_Pin;
  GPIO_InitStruct.Mode = GPIO_MODE_AF_PP;
  GPIO_InitStruct.Pull = GPIO_NOPULL;
  GPIO_InitStruct.Speed = GPIO_SPEED_FREQ_LOW;
  GPIO_InitStruct.Alternate = GPIO_AF3_DFSDM1;
  HAL_GPIO_Init(GPIOC, &GPIO_InitStruct);

  /*Configure GPIO pins : QSPI_D1_Pin QSPI_D0_Pin */
  GPIO_InitStruct.Pin = QSPI_D1_Pin|QSPI_D0_Pin;
  GPIO_InitStruct.Mode = GPIO_MODE_AF_PP;
  GPIO_InitStruct.Pull = GPIO_NOPULL;
  GPIO_InitStruct.Speed = GPIO_SPEED_FREQ_VERY_HIGH;
  GPIO_InitStruct.Alternate = GPIO_AF9_QUADSPI;
  HAL_GPIO_Init(GPIOC, &GPIO_InitStruct);

  /*Configure GPIO pin : ARD_D13_SCK_Pin */
  GPIO_InitStruct.Pin = ARD_D13_SCK_Pin;
  GPIO_InitStruct.Mode = GPIO_MODE_AF_PP;
  GPIO_InitStruct.Pull = GPIO_NOPULL;
  GPIO_InitStruct.Speed = GPIO_SPEED_FREQ_LOW;
  GPIO_InitStruct.Alternate = GPIO_AF5_SPI2;
  HAL_GPIO_Init(ARD_D13_SCK_GPIO_Port, &GPIO_InitStruct);

  /*Configure GPIO pins : NC4_Pin NC5_Pin uSD_Detect_Pin LCD_BL_CTRL_Pin */
  GPIO_InitStruct.Pin = NC4_Pin|NC5_Pin|uSD_Detect_Pin|LCD_BL_CTRL_Pin;
  GPIO_InitStruct.Mode = GPIO_MODE_INPUT;
  GPIO_InitStruct.Pull = GPIO_NOPULL;
  HAL_GPIO_Init(GPIOI, &GPIO_InitStruct);

  /*Configure GPIO pins : FMC_NBL2_Pin D27_Pin D26_Pin FMC_NBL3_Pin
                           D29_Pin D31_Pin D28_Pin D25_Pin
                           D30_Pin D24_Pin */
  GPIO_InitStruct.Pin = FMC_NBL2_Pin|D27_Pin|D26_Pin|FMC_NBL3_Pin
                          |D29_Pin|D31_Pin|D28_Pin|D25_Pin
                          |D30_Pin|D24_Pin;
  GPIO_InitStruct.Mode = GPIO_MODE_AF_PP;
  GPIO_InitStruct.Pull = GPIO_NOPULL;
  GPIO_InitStruct.Speed = GPIO_SPEED_FREQ_VERY_HIGH;
  GPIO_InitStruct.Alternate = GPIO_AF12_FMC;
  HAL_GPIO_Init(GPIOI, &GPIO_InitStruct);

  /*Configure GPIO pins : NC3_Pin NC2_Pin NC1_Pin NC8_Pin
                           NC7_Pin */
  GPIO_InitStruct.Pin = NC3_Pin|NC2_Pin|NC1_Pin|NC8_Pin
                          |NC7_Pin;
  GPIO_InitStruct.Mode = GPIO_MODE_INPUT;
  GPIO_InitStruct.Pull = GPIO_NOPULL;
  HAL_GPIO_Init(GPIOK, &GPIO_InitStruct);

  /*Configure GPIO pin : SPDIF_RX_Pin */
  GPIO_InitStruct.Pin = SPDIF_RX_Pin;
  GPIO_InitStruct.Mode = GPIO_MODE_AF_PP;
  GPIO_InitStruct.Pull = GPIO_NOPULL;
  GPIO_InitStruct.Speed = GPIO_SPEED_FREQ_LOW;
  GPIO_InitStruct.Alternate = GPIO_AF7_SPDIFRX;
  HAL_GPIO_Init(SPDIF_RX_GPIO_Port, &GPIO_InitStruct);

  /*Configure GPIO pins : RMII_RXER_Pin OTG_FS_OverCurrent_Pin */
  GPIO_InitStruct.Pin = RMII_RXER_Pin|OTG_FS_OverCurrent_Pin;
  GPIO_InitStruct.Mode = GPIO_MODE_INPUT;
  GPIO_InitStruct.Pull = GPIO_NOPULL;
  HAL_GPIO_Init(GPIOD, &GPIO_InitStruct);

  /*Configure GPIO pin : DFSDM_CKOUT_Pin */
  GPIO_InitStruct.Pin = DFSDM_CKOUT_Pin;
  GPIO_InitStruct.Mode = GPIO_MODE_AF_PP;
  GPIO_InitStruct.Pull = GPIO_NOPULL;
  GPIO_InitStruct.Speed = GPIO_SPEED_FREQ_LOW;
  GPIO_InitStruct.Alternate = GPIO_AF3_DFSDM1;
  HAL_GPIO_Init(DFSDM_CKOUT_GPIO_Port, &GPIO_InitStruct);

  /*Configure GPIO pin : SPI2_NSS_Pin */
  GPIO_InitStruct.Pin = SPI2_NSS_Pin;
  GPIO_InitStruct.Mode = GPIO_MODE_AF_PP;
  GPIO_InitStruct.Pull = GPIO_NOPULL;
  GPIO_InitStruct.Speed = GPIO_SPEED_FREQ_VERY_HIGH;
  GPIO_InitStruct.Alternate = GPIO_AF5_SPI2;
  HAL_GPIO_Init(SPI2_NSS_GPIO_Port, &GPIO_InitStruct);

  /*Configure GPIO pins : FMC_A0_Pin FMC_A1_Pin FMC_A2_Pin FMC_A3_Pin
                           FMC_A4_Pin FMC_A5_Pin FMC_A6_Pin FMC_A9_Pin
                           FMC_A7_Pin FMC_A8_Pin FMC_SDNRAS_Pin */
  GPIO_InitStruct.Pin = FMC_A0_Pin|FMC_A1_Pin|FMC_A2_Pin|FMC_A3_Pin
                          |FMC_A4_Pin|FMC_A5_Pin|FMC_A6_Pin|FMC_A9_Pin
                          |FMC_A7_Pin|FMC_A8_Pin|FMC_SDNRAS_Pin;
  GPIO_InitStruct.Mode = GPIO_MODE_AF_PP;
  GPIO_InitStruct.Pull = GPIO_NOPULL;
  GPIO_InitStruct.Speed = GPIO_SPEED_FREQ_VERY_HIGH;
  GPIO_InitStruct.Alternate = GPIO_AF12_FMC;
  HAL_GPIO_Init(GPIOF, &GPIO_InitStruct);

  /*Configure GPIO pin : WIFI_TX_Pin */
  GPIO_InitStruct.Pin = WIFI_TX_Pin;
  GPIO_InitStruct.Mode = GPIO_MODE_AF_PP;
  GPIO_InitStruct.Pull = GPIO_NOPULL;
  GPIO_InitStruct.Speed = GPIO_SPEED_FREQ_VERY_HIGH;
  GPIO_InitStruct.Alternate = GPIO_AF8_UART5;
  HAL_GPIO_Init(WIFI_TX_GPIO_Port, &GPIO_InitStruct);

  /*Configure GPIO pins : D23_Pin D21_Pin D22_Pin FMC_SDNME_Pin
                           FMC_SDNE0_Pin FMC_SDCKE0_Pin D20_Pin FMC_D_7_Pin
                           FMC_D19_Pin FMC_D16_Pin FMC_D18_Pin */
  GPIO_InitStruct.Pin = D23_Pin|D21_Pin|D22_Pin|FMC_SDNME_Pin
                          |FMC_SDNE0_Pin|FMC_SDCKE0_Pin|D20_Pin|FMC_D_7_Pin
                          |FMC_D19_Pin|FMC_D16_Pin|FMC_D18_Pin;
  GPIO_InitStruct.Mode = GPIO_MODE_AF_PP;
  GPIO_InitStruct.Pull = GPIO_NOPULL;
  GPIO_InitStruct.Speed = GPIO_SPEED_FREQ_VERY_HIGH;
  GPIO_InitStruct.Alternate = GPIO_AF12_FMC;
  HAL_GPIO_Init(GPIOH, &GPIO_InitStruct);

  /*Configure GPIO pin : ULPI_DIR_Pin */
  GPIO_InitStruct.Pin = ULPI_DIR_Pin;
  GPIO_InitStruct.Mode = GPIO_MODE_AF_PP;
  GPIO_InitStruct.Pull = GPIO_NOPULL;
  GPIO_InitStruct.Speed = GPIO_SPEED_FREQ_VERY_HIGH;
  GPIO_InitStruct.Alternate = GPIO_AF10_OTG_HS;
  HAL_GPIO_Init(ULPI_DIR_GPIO_Port, &GPIO_InitStruct);

  /*Configure GPIO pin : CEC_CLK_Pin */
  GPIO_InitStruct.Pin = CEC_CLK_Pin;
  GPIO_InitStruct.Mode = GPIO_MODE_AF_PP;
  GPIO_InitStruct.Pull = GPIO_NOPULL;
  GPIO_InitStruct.Speed = GPIO_SPEED_FREQ_LOW;
  GPIO_InitStruct.Alternate = GPIO_AF0_MCO;
  HAL_GPIO_Init(CEC_CLK_GPIO_Port, &GPIO_InitStruct);

  /*Configure GPIO pin : LCD_INT_Pin */
  GPIO_InitStruct.Pin = LCD_INT_Pin;
  GPIO_InitStruct.Mode = GPIO_MODE_EVT_RISING;
  GPIO_InitStruct.Pull = GPIO_NOPULL;
  HAL_GPIO_Init(LCD_INT_GPIO_Port, &GPIO_InitStruct);

  /*Configure GPIO pin : ARD_D5_PWM_Pin */
  GPIO_InitStruct.Pin = ARD_D5_PWM_Pin;
  GPIO_InitStruct.Mode = GPIO_MODE_AF_PP;
  GPIO_InitStruct.Pull = GPIO_NOPULL;
  GPIO_InitStruct.Speed = GPIO_SPEED_FREQ_LOW;
  GPIO_InitStruct.Alternate = GPIO_AF2_TIM3;
  HAL_GPIO_Init(ARD_D5_PWM_GPIO_Port, &GPIO_InitStruct);

  /*Configure GPIO pins : ARD_D0_RX_Pin ARDUINO_TX_D1_Pin */
  GPIO_InitStruct.Pin = ARD_D0_RX_Pin|ARDUINO_TX_D1_Pin;
  GPIO_InitStruct.Mode = GPIO_MODE_AF_PP;
  GPIO_InitStruct.Pull = GPIO_NOPULL;
  GPIO_InitStruct.Speed = GPIO_SPEED_FREQ_VERY_HIGH;
  GPIO_InitStruct.Alternate = GPIO_AF8_USART6;
  HAL_GPIO_Init(GPIOC, &GPIO_InitStruct);

  /*Configure GPIO pin : ULPI_NXT_Pin */
  GPIO_InitStruct.Pin = ULPI_NXT_Pin;
  GPIO_InitStruct.Mode = GPIO_MODE_AF_PP;
  GPIO_InitStruct.Pull = GPIO_NOPULL;
  GPIO_InitStruct.Speed = GPIO_SPEED_FREQ_VERY_HIGH;
  GPIO_InitStruct.Alternate = GPIO_AF10_OTG_HS;
  HAL_GPIO_Init(ULPI_NXT_GPIO_Port, &GPIO_InitStruct);

  /*Configure GPIO pin : SAI1_MCLKA_Pin */
  GPIO_InitStruct.Pin = SAI1_MCLKA_Pin;
  GPIO_InitStruct.Mode = GPIO_MODE_AF_PP;
  GPIO_InitStruct.Pull = GPIO_NOPULL;
  GPIO_InitStruct.Speed = GPIO_SPEED_FREQ_LOW;
  GPIO_InitStruct.Alternate = GPIO_AF6_SAI1;
  HAL_GPIO_Init(SAI1_MCLKA_GPIO_Port, &GPIO_InitStruct);

  /*Configure GPIO pins : EXT_SDA_Pin EXT_SCL_Pin */
  GPIO_InitStruct.Pin = EXT_SDA_Pin|EXT_SCL_Pin;
  GPIO_InitStruct.Mode = GPIO_MODE_INPUT;
  GPIO_InitStruct.Pull = GPIO_NOPULL;
  HAL_GPIO_Init(GPIOG, &GPIO_InitStruct);

  /*Configure GPIO pin : ARD_D6_PWM_Pin */
  GPIO_InitStruct.Pin = ARD_D6_PWM_Pin;
  GPIO_InitStruct.Mode = GPIO_MODE_AF_PP;
  GPIO_InitStruct.Pull = GPIO_NOPULL;
  GPIO_InitStruct.Speed = GPIO_SPEED_FREQ_LOW;
  GPIO_InitStruct.Alternate = GPIO_AF3_TIM11;
  HAL_GPIO_Init(ARD_D6_PWM_GPIO_Port, &GPIO_InitStruct);

  /*Configure GPIO pin : ARD_D3_PWM_Pin */
  GPIO_InitStruct.Pin = ARD_D3_PWM_Pin;
  GPIO_InitStruct.Mode = GPIO_MODE_AF_PP;
  GPIO_InitStruct.Pull = GPIO_NOPULL;
  GPIO_InitStruct.Speed = GPIO_SPEED_FREQ_LOW;
  GPIO_InitStruct.Alternate = GPIO_AF3_TIM10;
  HAL_GPIO_Init(ARD_D3_PWM_GPIO_Port, &GPIO_InitStruct);

  /*Configure GPIO pins : ARDUINO_A1_Pin ARDUINO_A2_Pin ARDUINO_A3_Pin */
  GPIO_InitStruct.Pin = ARDUINO_A1_Pin|ARDUINO_A2_Pin|ARDUINO_A3_Pin;
  GPIO_InitStruct.Mode = GPIO_MODE_ANALOG;
  GPIO_InitStruct.Pull = GPIO_NOPULL;
  HAL_GPIO_Init(GPIOF, &GPIO_InitStruct);

  /*Configure GPIO pin : ULPI_STP_Pin */
  GPIO_InitStruct.Pin = ULPI_STP_Pin;
  GPIO_InitStruct.Mode = GPIO_MODE_AF_PP;
  GPIO_InitStruct.Pull = GPIO_NOPULL;
  GPIO_InitStruct.Speed = GPIO_SPEED_FREQ_VERY_HIGH;
  GPIO_InitStruct.Alternate = GPIO_AF10_OTG_HS;
  HAL_GPIO_Init(ULPI_STP_GPIO_Port, &GPIO_InitStruct);

  /*Configure GPIO pins : RMII_MDC_Pin RMII_RXD0_Pin RMII_RXD1_Pin */
  GPIO_InitStruct.Pin = RMII_MDC_Pin|RMII_RXD0_Pin|RMII_RXD1_Pin;
  GPIO_InitStruct.Mode = GPIO_MODE_AF_PP;
  GPIO_InitStruct.Pull = GPIO_NOPULL;
  GPIO_InitStruct.Speed = GPIO_SPEED_FREQ_VERY_HIGH;
  GPIO_InitStruct.Alternate = GPIO_AF11_ETH;
  HAL_GPIO_Init(GPIOC, &GPIO_InitStruct);

  /*Configure GPIO pin : ARD_A2_Pin */
  GPIO_InitStruct.Pin = ARD_A2_Pin;
  GPIO_InitStruct.Mode = GPIO_MODE_ANALOG;
  GPIO_InitStruct.Pull = GPIO_NOPULL;
  HAL_GPIO_Init(ARD_A2_GPIO_Port, &GPIO_InitStruct);

  /*Configure GPIO pin : PB2 */
  GPIO_InitStruct.Pin = GPIO_PIN_2;
  GPIO_InitStruct.Mode = GPIO_MODE_AF_PP;
  GPIO_InitStruct.Pull = GPIO_NOPULL;
  GPIO_InitStruct.Speed = GPIO_SPEED_FREQ_VERY_HIGH;
  GPIO_InitStruct.Alternate = GPIO_AF9_QUADSPI;
  HAL_GPIO_Init(GPIOB, &GPIO_InitStruct);

  /*Configure GPIO pin : AUDIO_SCL_Pin */
  GPIO_InitStruct.Pin = AUDIO_SCL_Pin;
  GPIO_InitStruct.Mode = GPIO_MODE_AF_OD;
  GPIO_InitStruct.Pull = GPIO_NOPULL;
  GPIO_InitStruct.Speed = GPIO_SPEED_FREQ_VERY_HIGH;
  GPIO_InitStruct.Alternate = GPIO_AF4_I2C4;
  HAL_GPIO_Init(AUDIO_SCL_GPIO_Port, &GPIO_InitStruct);

  /*Configure GPIO pin : QSPI_D3_Pin */
  GPIO_InitStruct.Pin = QSPI_D3_Pin;
  GPIO_InitStruct.Mode = GPIO_MODE_AF_PP;
  GPIO_InitStruct.Pull = GPIO_NOPULL;
  GPIO_InitStruct.Speed = GPIO_SPEED_FREQ_VERY_HIGH;
  GPIO_InitStruct.Alternate = GPIO_AF9_QUADSPI;
  HAL_GPIO_Init(QSPI_D3_GPIO_Port, &GPIO_InitStruct);

  /*Configure GPIO pins : RMII_REF_CLK_Pin RMII_MDIO_Pin RMII_CRS_DV_Pin */
  GPIO_InitStruct.Pin = RMII_REF_CLK_Pin|RMII_MDIO_Pin|RMII_CRS_DV_Pin;
  GPIO_InitStruct.Mode = GPIO_MODE_AF_PP;
  GPIO_InitStruct.Pull = GPIO_NOPULL;
  GPIO_InitStruct.Speed = GPIO_SPEED_FREQ_VERY_HIGH;
  GPIO_InitStruct.Alternate = GPIO_AF11_ETH;
  HAL_GPIO_Init(GPIOA, &GPIO_InitStruct);

  /*Configure GPIO pin : B_USER_Pin */
  GPIO_InitStruct.Pin = B_USER_Pin;
  GPIO_InitStruct.Mode = GPIO_MODE_IT_RISING;
  GPIO_InitStruct.Pull = GPIO_NOPULL;
  HAL_GPIO_Init(B_USER_GPIO_Port, &GPIO_InitStruct);

  /*Configure GPIO pins : ARD_A1_Pin ARD_A0_Pin */
  GPIO_InitStruct.Pin = ARD_A1_Pin|ARD_A0_Pin;
  GPIO_InitStruct.Mode = GPIO_MODE_ANALOG;
  GPIO_InitStruct.Pull = GPIO_NOPULL;
  HAL_GPIO_Init(GPIOA, &GPIO_InitStruct);

  /*Configure GPIO pin : SPDIF_TX_Pin */
  GPIO_InitStruct.Pin = SPDIF_TX_Pin;
  GPIO_InitStruct.Mode = GPIO_MODE_AF_PP;
  GPIO_InitStruct.Pull = GPIO_NOPULL;
  GPIO_InitStruct.Speed = GPIO_SPEED_FREQ_LOW;
  GPIO_InitStruct.Alternate = GPIO_AF10_SAI2;
  HAL_GPIO_Init(SPDIF_TX_GPIO_Port, &GPIO_InitStruct);

  /*Configure GPIO pin : EXT_RST_Pin */
  GPIO_InitStruct.Pin = EXT_RST_Pin;
  GPIO_InitStruct.Mode = GPIO_MODE_INPUT;
  GPIO_InitStruct.Pull = GPIO_NOPULL;
  HAL_GPIO_Init(EXT_RST_GPIO_Port, &GPIO_InitStruct);

  /*Configure GPIO pins : ULPI_CLK_Pin ULPI_D0_Pin */
  GPIO_InitStruct.Pin = ULPI_CLK_Pin|ULPI_D0_Pin;
  GPIO_InitStruct.Mode = GPIO_MODE_AF_PP;
  GPIO_InitStruct.Pull = GPIO_NOPULL;
  GPIO_InitStruct.Speed = GPIO_SPEED_FREQ_VERY_HIGH;
  GPIO_InitStruct.Alternate = GPIO_AF10_OTG_HS;
  HAL_GPIO_Init(GPIOA, &GPIO_InitStruct);

  /*Configure GPIO pin : DSIHOST_TE_Pin */
  GPIO_InitStruct.Pin = DSIHOST_TE_Pin;
  GPIO_InitStruct.Mode = GPIO_MODE_AF_PP;
  GPIO_InitStruct.Pull = GPIO_NOPULL;
  GPIO_InitStruct.Speed = GPIO_SPEED_FREQ_LOW;
  GPIO_InitStruct.Alternate = GPIO_AF13_DSI;
  HAL_GPIO_Init(DSIHOST_TE_GPIO_Port, &GPIO_InitStruct);

  /*Configure GPIO pin : ARDUINO_PWM_D6_Pin */
  GPIO_InitStruct.Pin = ARDUINO_PWM_D6_Pin;
  GPIO_InitStruct.Mode = GPIO_MODE_AF_PP;
  GPIO_InitStruct.Pull = GPIO_NOPULL;
  GPIO_InitStruct.Speed = GPIO_SPEED_FREQ_LOW;
  GPIO_InitStruct.Alternate = GPIO_AF9_TIM12;
  HAL_GPIO_Init(ARDUINO_PWM_D6_GPIO_Port, &GPIO_InitStruct);

  /*Configure GPIO pins : ARDUINO_MISO_D12_Pin ARDUINO_MOSI_PWM_D11_Pin */
  GPIO_InitStruct.Pin = ARDUINO_MISO_D12_Pin|ARDUINO_MOSI_PWM_D11_Pin;
  GPIO_InitStruct.Mode = GPIO_MODE_AF_PP;
  GPIO_InitStruct.Pull = GPIO_NOPULL;
  GPIO_InitStruct.Speed = GPIO_SPEED_FREQ_LOW;
  GPIO_InitStruct.Alternate = GPIO_AF5_SPI2;
  HAL_GPIO_Init(GPIOB, &GPIO_InitStruct);

}

void StartDefaultTask(void const * argument)
{
  /* USER CODE BEGIN 5 */
  /* Infinite loop */
  for(;;)
  {
    osDelay(10000);
  }
  /* USER CODE END 5 */
}

void cpu_start(void const * argument)
{
  /* USER CODE BEGIN cpu_start */
  /* Infinite loop */
  for(;;)
  {
    cpu_run(NULL);
  }
  /* USER CODE END cpu_start */
}

void ui_start(void const * argument)
{
  /* USER CODE BEGIN ui_start */
  /* Infinite loop */
  for(;;)
  {
    emu_run("special.gb");
  }
  /* USER CODE END ui_start */
}

void HAL_TIM_PeriodElapsedCallback(TIM_HandleTypeDef *htim)
{
  if (htim->Instance == TIM1) {
    HAL_IncTick();
  }
}

void Error_Handler(void)
{
  __disable_irq();
  while (1)
  {
  }
}
